VERSION "cheesecc-dbw-0.1"

NS_ :

BS_:

BU_: CHEESECC_APP EPS POWERTRAIN VEHICLE GATEWAY TESTER

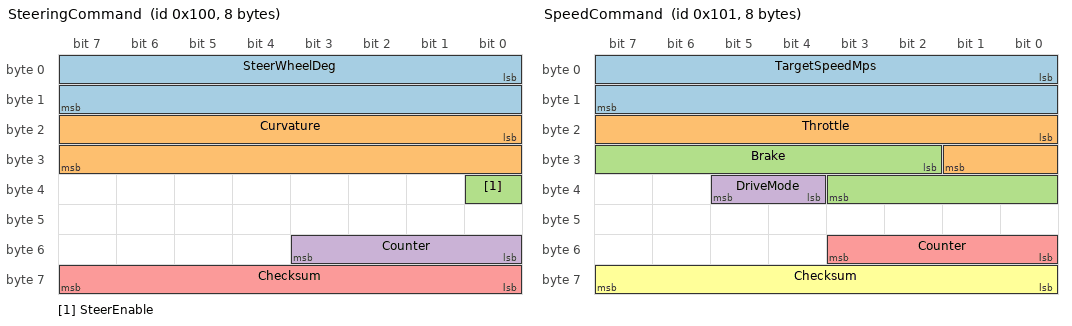
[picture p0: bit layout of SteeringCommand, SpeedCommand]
BO_ 256 SteeringCommand: 8 CHEESECC_APP
 SG_ SteerWheelDeg : 0|16@1- (0.1,0) [-540|540] "deg" EPS
 SG_ Curvature : 16|16@1- (0.0001,0) [-0.5|0.5] "1/m" EPS
 SG_ SteerEnable : 32|1@1+ (1,0) [0|1] "" EPS
 SG_ Counter : 48|4@1+ (1,0) [0|15] "" EPS
 SG_ Checksum : 56|8@1+ (1,0) [0|255] "" EPS

BO_ 257 SpeedCommand: 8 CHEESECC_APP
 SG_ TargetSpeedMps : 0|16@1+ (0.01,0) [0|60] "m/s" POWERTRAIN
 SG_ Throttle : 16|10@1+ (0.001,0) [0|1] "" POWERTRAIN
 SG_ Brake : 26|10@1+ (0.001,0) [0|1] "" POWERTRAIN
 SG_ DriveMode : 36|2@1+ (1,0) [0|3] "" POWERTRAIN
 SG_ Counter : 48|4@1+ (1,0) [0|15] "" POWERTRAIN
 SG_ Checksum : 56|8@1+ (1,0) [0|255] "" POWERTRAIN

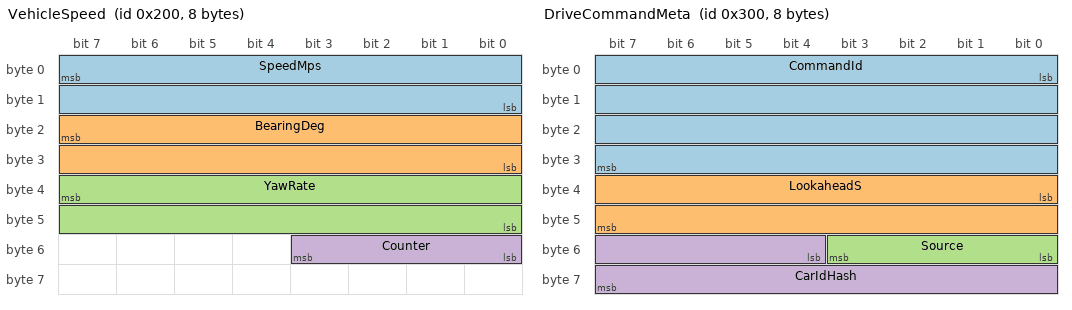
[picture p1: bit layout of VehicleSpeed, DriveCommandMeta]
BO_ 512 VehicleSpeed: 8 VEHICLE
 SG_ SpeedMps : 7|16@0+ (0.01,0) [0|100] "m/s" CHEESECC_APP
 SG_ BearingDeg : 23|16@0+ (0.01,0) [0|360] "deg" CHEESECC_APP
 SG_ YawRate : 39|16@0- (0.001,0) [-2|2] "rad/s" CHEESECC_APP
 SG_ Counter : 51|4@0+ (1,0) [0|15] "" CHEESECC_APP

BO_ 768 DriveCommandMeta: 8 CHEESECC_APP
 SG_ CommandId : 0|32@1+ (1,0) [0|4294967295] "" GATEWAY
 SG_ LookaheadS : 32|16@1+ (0.01,0) [0|600] "s" GATEWAY
 SG_ Source : 48|4@1+ (1,0) [0|15] "" GATEWAY
 SG_ CarIdHash : 52|12@1+ (1,0) [0|4095] "" GATEWAY

BO_ 2566849296 DriveCommandGeo: 8 CHEESECC_APP
 SG_ GeoMux M : 0|8@1+ (1,0) [0|3] "" GATEWAY
 SG_ Latitude m0 : 8|32@1- (1E-007,0) [-90|90] "deg" GATEWAY
 SG_ Longitude m1 : 8|32@1- (1E-007,0) [-180|180] "deg" GATEWAY
 SG_ FromLatitude m2 : 8|32@1- (1E-007,0) [-90|90] "deg" GATEWAY
 SG_ FromLongitude m3 : 8|32@1- (1E-007,0) [-180|180] "deg" GATEWAY

BO_ 1025 TrajectoryPreview: 16 CHEESECC_APP
 SG_ PreviewCurvature : 0|32@1- (1,0) [0|0] "1/m" GATEWAY
 SG_ PreviewSpeedMps : 32|32@1- (1,0) [0|0] "m/s" GATEWAY
 SG_ PreviewHorizonS : 64|16@1+ (0.01,0) [0|600] "s" GATEWAY

BO_ 2016 DiagRequest: 8 TESTER

BO_ 2024 DiagResponse: 8 GATEWAY

CM_ "CHEESECC drive-by-wire network. Signals mirror the app's DriveCommand
(theapp/CHEESECC/Domain/Command/DriveCommand.swift).";
CM_ BU_ EPS "Electric power steering actuator";
CM_ BO_ 256 "Steering request from the phone/stack. DriveCommand.steerWheelDeg, .curvature";
CM_ BO_ 257 "Longitudinal request. DriveCommand.targetSpeedMps, .throttle, .brake";
CM_ BO_ 768 "DriveCommand bookkeeping: id (low 32 bits), lookaheadS, source, hash of carId";
CM_ BO_ 2566849296 "DriveCommand geo fields, multiplexed: 0=latitude 1=longitude 2=fromLatitude 3=fromLongitude";
CM_ SG_ 256 SteerWheelDeg "Steering-wheel angle request, positive = left (CCW)";
CM_ SG_ 256 Checksum "Sum of bytes 0..6 modulo 256, XOR 0xFF";
CM_ SG_ 512 SpeedMps "Measured vehicle speed. DriveCommand.speedMps";
CM_ SG_ 512 BearingDeg "Heading clockwise from north. DriveCommand.bearingDeg";

BA_DEF_ BO_ "GenMsgCycleTime" INT 0 10000;
BA_DEF_ BO_ "GenMsgSendType" STRING ;
BA_DEF_DEF_ "GenMsgCycleTime" 0;
BA_DEF_DEF_ "GenMsgSendType" "Cyclic";
BA_ "GenMsgCycleTime" BO_ 256 20;
BA_ "GenMsgCycleTime" BO_ 257 20;
BA_ "GenMsgCycleTime" BO_ 512 10;
BA_ "GenMsgCycleTime" BO_ 768 100;
BA_ "GenMsgCycleTime" BO_ 2566849296 100;
BA_ "GenMsgSendType" BO_ 2016 "Event";
BA_ "GenMsgSendType" BO_ 2024 "Event";

VAL_ 257 DriveMode 0 "Manual" 1 "Assist" 2 "Auto" 3 "Fault" ;
VAL_ 768 Source 0 "app" 1 "control" 2 "teleop" 3 "replay" 4 "sim" 15 "unknown" ;
VAL_ 2566849296 GeoMux 0 "Latitude" 1 "Longitude" 2 "FromLatitude" 3 "FromLongitude" ;

SIG_VALTYPE_ 1025 PreviewCurvature : 1;
SIG_VALTYPE_ 1025 PreviewSpeedMps : 1;
